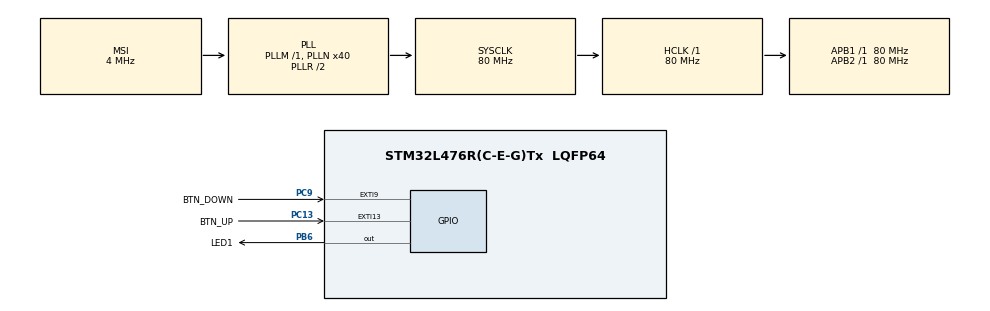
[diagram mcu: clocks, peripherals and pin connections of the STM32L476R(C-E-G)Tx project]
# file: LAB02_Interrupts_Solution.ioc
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Mcu.Family=STM32L4
Mcu.Name=STM32L476R(C-E-G)Tx
Mcu.Package=LQFP64
NVIC.EXTI15_10_IRQn=true\:0\:0\:false\:false\:true\:true\:true\:true
NVIC.EXTI9_5_IRQn=true\:0\:0\:false\:false\:true\:true\:true\:true
NVIC.PriorityGroup=NVIC_PRIORITYGROUP_4
PB6.GPIO_Label=LED1
PB6.Signal=GPIO_Output
PC13.GPIO_Label=BTN_UP
PC13.GPIO_ModeDefaultEXTI=GPIO_MODE_IT_FALLING
PC13.Signal=GPXTI13
PC9.GPIO_Label=BTN_DOWN
PC9.GPIO_ModeDefaultEXTI=GPIO_MODE_IT_FALLING
PC9.Signal=GPXTI9
ProjectManager.HeapSize=0x200
ProjectManager.StackSize=0x400
ProjectManager.TargetToolchain=STM32CubeIDE
RCC.ADCFreq_Value=16000000
RCC.AHBFreq_Value=80000000
RCC.APB1Freq_Value=80000000
RCC.APB1TimFreq_Value=80000000
RCC.APB2Freq_Value=80000000
RCC.APB2TimFreq_Value=80000000
RCC.CortexFreq_Value=80000000
RCC.HCLKFreq_Value=80000000
RCC.HSE_VALUE=8000000
RCC.HSI_VALUE=16000000
RCC.LSE_VALUE=32768
RCC.MSI_VALUE=4000000
RCC.PLLN=40
RCC.SYSCLKFreq_VALUE=80000000
RCC.SYSCLKSource=RCC_SYSCLKSOURCE_PLLCLK
RCC.USBFreq_Value=16000000
RCC.VCOOutputFreq_Value=160000000
board=custom

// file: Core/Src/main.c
/* USER CODE BEGIN Header */
/**
 * @file main.c
 * @brief External Interrupts Exercise.
 * @author Philipp Schilk, 2023
 */
/* USER CODE END Header */
#include "main.h"

/* USER CODE BEGIN PV */
// TODO: Create a volatile uint32_t variable that stores the current delay
//       length in milliseconds.
//$ START SOL
volatile uint32_t delay_period_ms = 500;
//$ END
/* USER CODE END PV */

void SystemClock_Config(void);
static void MX_GPIO_Init(void);

int main(void) {

  /* MCU Configuration--------------------------------------------------------*/

  /* Reset of all peripherals, Initializes the Flash interface and the Systick. */
  HAL_Init();

  /* Configure the system clock */
  SystemClock_Config();

  /* Initialize all configured peripherals */
  MX_GPIO_Init();

  /* Infinite loop */
  /* USER CODE BEGIN WHILE */
  while (1) {
    // TODO: Toogle LED1, then delay for the period of time currently
    //       stored in your volatile global variable.
    //$ START SOL
    HAL_Delay(delay_period_ms);
    HAL_GPIO_TogglePin(LED1_GPIO_Port, LED1_Pin);
    //$ END

    /* USER CODE END WHILE */

  }
}

void SystemClock_Config(void) {
  RCC_OscInitTypeDef RCC_OscInitStruct = {0};
  RCC_ClkInitTypeDef RCC_ClkInitStruct = {0};

  /** Configure the main internal regulator output voltage
   */
  if (HAL_PWREx_ControlVoltageScaling(PWR_REGULATOR_VOLTAGE_SCALE1) != HAL_OK) {
    Error_Handler();
  }

  /** Initializes the RCC Oscillators according to the specified parameters
   * in the RCC_OscInitTypeDef structure.
   */
  RCC_OscInitStruct.OscillatorType = RCC_OSCILLATORTYPE_MSI;
  RCC_OscInitStruct.MSIState = RCC_MSI_ON;
  RCC_OscInitStruct.MSICalibrationValue = 0;
  RCC_OscInitStruct.MSIClockRange = RCC_MSIRANGE_6;
  RCC_OscInitStruct.PLL.PLLState = RCC_PLL_ON;
  RCC_OscInitStruct.PLL.PLLSource = RCC_PLLSOURCE_MSI;
  RCC_OscInitStruct.PLL.PLLM = 1;
  RCC_OscInitStruct.PLL.PLLN = 40;
  RCC_OscInitStruct.PLL.PLLP = RCC_PLLP_DIV7;
  RCC_OscInitStruct.PLL.PLLQ = RCC_PLLQ_DIV2;
  RCC_OscInitStruct.PLL.PLLR = RCC_PLLR_DIV2;
  if (HAL_RCC_OscConfig(&RCC_OscInitStruct) != HAL_OK) {
    Error_Handler();
  }

  /** Initializes the CPU, AHB and APB buses clocks
   */
  RCC_ClkInitStruct.ClockType = RCC_CLOCKTYPE_HCLK | RCC_CLOCKTYPE_SYSCLK | RCC_CLOCKTYPE_PCLK1 | RCC_CLOCKTYPE_PCLK2;
  RCC_ClkInitStruct.SYSCLKSource = RCC_SYSCLKSOURCE_PLLCLK;
  RCC_ClkInitStruct.AHBCLKDivider = RCC_SYSCLK_DIV1;
  RCC_ClkInitStruct.APB1CLKDivider = RCC_HCLK_DIV1;
  RCC_ClkInitStruct.APB2CLKDivider = RCC_HCLK_DIV1;

  if (HAL_RCC_ClockConfig(&RCC_ClkInitStruct, FLASH_LATENCY_4) != HAL_OK) {
    Error_Handler();
  }
}

static void MX_GPIO_Init(void) {
  GPIO_InitTypeDef GPIO_InitStruct = {0};
  /* USER CODE BEGIN MX_GPIO_Init_1 */
  //$ START SOL
  /* USER CODE END MX_GPIO_Init_1 */

  /* GPIO Ports Clock Enable */
  __HAL_RCC_GPIOC_CLK_ENABLE();
  __HAL_RCC_GPIOB_CLK_ENABLE();

  /*Configure GPIO pin Output Level */
  HAL_GPIO_WritePin(LED1_GPIO_Port, LED1_Pin, GPIO_PIN_RESET);

  /*Configure GPIO pins : BTN_UP_Pin BTN_DOWN_Pin */
  GPIO_InitStruct.Pin = BTN_UP_Pin | BTN_DOWN_Pin;
  GPIO_InitStruct.Mode = GPIO_MODE_IT_FALLING;
  GPIO_InitStruct.Pull = GPIO_NOPULL;
  HAL_GPIO_Init(GPIOC, &GPIO_InitStruct);

  /*Configure GPIO pin : LED1_Pin */
  GPIO_InitStruct.Pin = LED1_Pin;
  GPIO_InitStruct.Mode = GPIO_MODE_OUTPUT_PP;
  GPIO_InitStruct.Pull = GPIO_NOPULL;
  GPIO_InitStruct.Speed = GPIO_SPEED_FREQ_LOW;
  HAL_GPIO_Init(LED1_GPIO_Port, &GPIO_InitStruct);

  /* EXTI interrupt init*/
  HAL_NVIC_SetPriority(EXTI9_5_IRQn, 0, 0);
  HAL_NVIC_EnableIRQ(EXTI9_5_IRQn);

  HAL_NVIC_SetPriority(EXTI15_10_IRQn, 0, 0);
  HAL_NVIC_EnableIRQ(EXTI15_10_IRQn);

  /* USER CODE BEGIN MX_GPIO_Init_2 */
  //$ END
  /* USER CODE END MX_GPIO_Init_2 */
}

/* USER CODE BEGIN 4 */

// TODO: Implement the 'void HAL_GPIO_EXTI_Callback(uint16_t GPIO_Pin)' callback function
//       which gets called by the GPIO external interrupt handler.
//       Within, check if the up or the down button trigger the interrupt, and
//       increase or decrease the delay period stored in your global volatile
//       variable by 50ms respectively.
//       Make sure to prevent underflows and limit the delay range!
//       Your code should not adjust the beyond a range of 50ms to 1000ms.
//$ START SOL
void HAL_GPIO_EXTI_Callback(uint16_t GPIO_Pin) {
  if (GPIO_Pin == BTN_UP_Pin) {
    delay_period_ms = delay_period_ms >= 1000 ? 1000 : delay_period_ms + 50;
  }
  if (GPIO_Pin == BTN_DOWN_Pin) {
    delay_period_ms = delay_period_ms <= 50 ? 50 : delay_period_ms - 50;
  }
}
//$ END

/* USER CODE END 4 */

void Error_Handler(void) {
}
